VERSION ""

NS_ :

BS_:

BU_: AHRS PDM BCU STW Gigabox ADL Bosch_YawRate_Sensor CSI_5_REAR_left CSI_6_REAR_right CSI_4_DASH CSI_3_Front_Middle ECU Host CSI_1_Front_Left CSI_2_Front_Right
VAL_TABLE_ ERROR_IDs 5 "Lost BMS Message (BMS FAULT)" 4 "Lost BMS Message" 3 "Overtemperature" 2 "Undervoltage" 1 "Overvoltage" 0 "undefined" ;
VAL_TABLE_ SC_open 1 "SC closed" 0 "SC open" ;
VAL_TABLE_ TLE_Diag_Channel 3 "normal function" 2 "Overload, Overtemp" 1 "open Load" 0 "short to GND" ;
VAL_TABLE_ AIR_State 2 "AIR CLOSED" 1 "PRECHARGE" 0 "AIR OPEN" -1 "AIR ERROR" ;
VAL_TABLE_ SC 1 "ok" 0 "fault" ;
VAL_TABLE_ Channel_Status 2 "OVERLOAD" 1 "ON" 0 "OFF" ;
VAL_TABLE_ Status_Continental 4369 "Reserved" 4368 "Signal faulty" 4353 "Sensor does not exist" 4113 "Reserved" 4097 "Sensor does not exist" 4096 "Signal within range" 273 "Reserved" 257 "Sensor does not exist" 256 "Signal within range" 17 "Reserved" 1 "Sensor does not exist" 0 "Signal within range" 4352 "Signal within range" 4112 "Signal faulty" 272 "Signal faulty" 16 "Signal faulty" ;
VAL_TABLE_ AnAus 1 "1" 0 "0" ;
VAL_TABLE_ Mount_Position 7 "rotated +270 z reflection xy" 6 "rotated +180 z reflection xy" 5 "rotated +90 zreflection xy" 4 "Standard reflection xy" 3 "rotated +270 z" 2 "rotated +180 z" 1 "rotated +90 z" 0 "Standard" ;
VAL_TABLE_ Format_CAN_Signals 1 "Motorola Format" 0 "Intel Format" ;

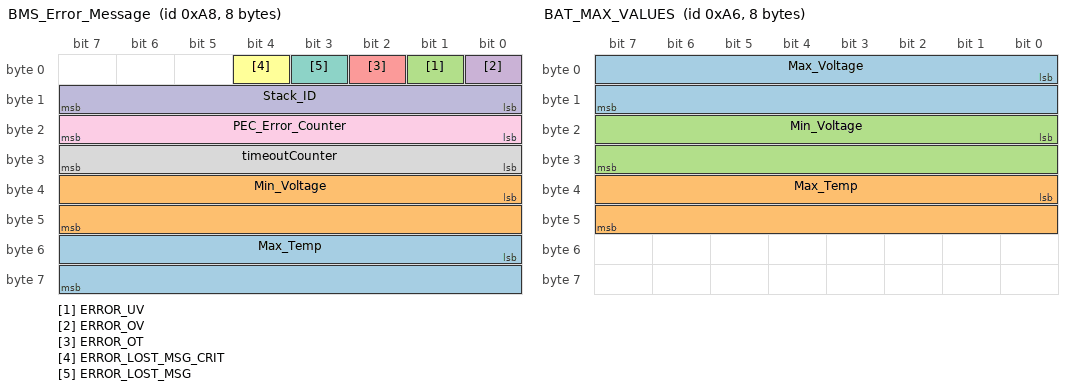
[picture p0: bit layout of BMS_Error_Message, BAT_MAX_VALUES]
BO_ 168 BMS_Error_Message: 8 BCU
 SG_ Max_Temp : 48|16@1- (0.01,0) [0|0] "°C" Vector__XXX
 SG_ Min_Voltage : 32|16@1+ (0.0001,0) [0|6.5535] "" Vector__XXX
 SG_ ERROR_UV : 1|1@1+ (1,0) [0|0] "" Vector__XXX
 SG_ ERROR_OV : 0|1@1+ (1,0) [0|0] "" Vector__XXX
 SG_ ERROR_OT : 2|1@1+ (1,0) [0|0] "" Vector__XXX
 SG_ ERROR_LOST_MSG_CRIT : 4|1@1+ (1,0) [0|0] "" Vector__XXX
 SG_ ERROR_LOST_MSG : 3|1@1+ (1,0) [0|0] "" Vector__XXX
 SG_ timeoutCounter : 24|8@1+ (1,0) [0|0] "" Vector__XXX
 SG_ PEC_Error_Counter : 16|8@1+ (1,0) [0|0] "" Vector__XXX
 SG_ Stack_ID : 8|8@1+ (1,0) [0|0] "" Vector__XXX

BO_ 166 BAT_MAX_VALUES: 8 BCU
 SG_ Max_Voltage : 0|16@1+ (0.0001,0) [0|6.5535] "V" Vector__XXX
 SG_ Max_Temp : 32|16@1- (0.01,0) [0|0] "°C" Vector__XXX
 SG_ Min_Voltage : 16|16@1+ (0.0001,0) [0|6.5535] "" Vector__XXX

BO_ 1540 IMD_Control_CSI0: 8 BCU
 SG_ IMD_LED : 0|1@1+ (1,0) [0|0] "" Vector__XXX

BO_ 1556 Precharge_LED_Control_CSI1: 8 BCU
 SG_ Precharge_LED : 0|1@1- (1,0) [0|0] "" Vector__XXX

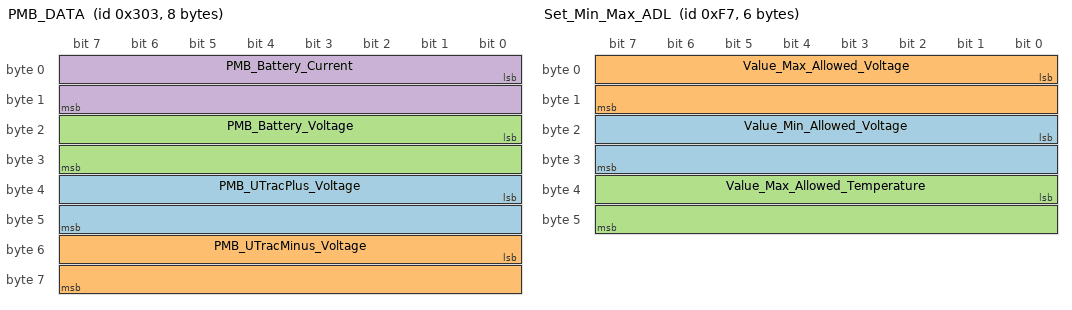
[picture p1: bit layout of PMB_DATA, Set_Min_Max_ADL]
BO_ 771 PMB_DATA: 8 STW
 SG_ PMB_UTracPlus_Voltage : 32|16@1- (0.025,0) [-820|820] "V"  Gigabox
 SG_ PMB_UTracMinus_Voltage : 48|16@1- (0.025,0) [-820|820] "V"  Gigabox
 SG_ PMB_Battery_Voltage : 16|16@1- (0.025,0) [-819.2|819.175] "V"  Gigabox
 SG_ PMB_Battery_Current : 0|16@1- (0.025,0) [-819.2|819.175] "A"  Gigabox

BO_ 167 AIR_Stuck: 4 BCU
 SG_ AIR_Stuck_Plus : 0|16@1- (1,0) [0|0] ""  ADL
 SG_ AIR_Stuck_Minus : 16|16@1- (1,0) [0|0] ""  ADL

BO_ 247 Set_Min_Max_ADL: 6 ADL
 SG_ Value_Min_Allowed_Voltage : 16|16@1+ (0.0001,0) [0|0] "V" Vector__XXX
 SG_ Value_Max_Allowed_Voltage : 0|16@1+ (0.0001,0) [0|0] "V" Vector__XXX
 SG_ Value_Max_Allowed_Temperature : 32|16@1- (0.01,0) [0|0] "C" Vector__XXX

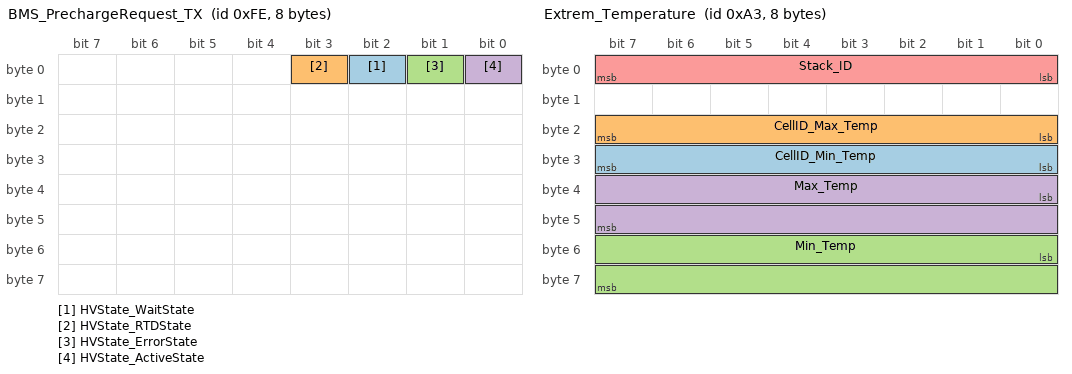
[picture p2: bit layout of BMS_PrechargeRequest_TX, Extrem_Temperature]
BO_ 254 BMS_PrechargeRequest_TX: 8 Gigabox
 SG_ HVState_WaitState : 2|1@1+ (1,0) [0|0] "" Vector__XXX
 SG_ HVState_RTDState : 3|1@1+ (1,0) [0|0] "" Vector__XXX
 SG_ HVState_ErrorState : 1|1@1+ (1,0) [0|0] "" Vector__XXX
 SG_ HVState_ActiveState : 0|1@1+ (1,0) [0|0] "" Vector__XXX

BO_ 163 Extrem_Temperature: 8 BCU
 SG_ CellID_Min_Temp : 24|8@1+ (1,0) [0|0] "" Vector__XXX
 SG_ CellID_Max_Temp : 16|8@1+ (1,0) [0|0] "" Vector__XXX
 SG_ Min_Temp : 48|16@1- (0.01,0) [0|0] "°C" Vector__XXX
 SG_ Max_Temp : 32|16@1- (0.01,0) [0|0] "°C" Vector__XXX
 SG_ Stack_ID : 0|8@1+ (1,0) [0|0] "" Vector__XXX

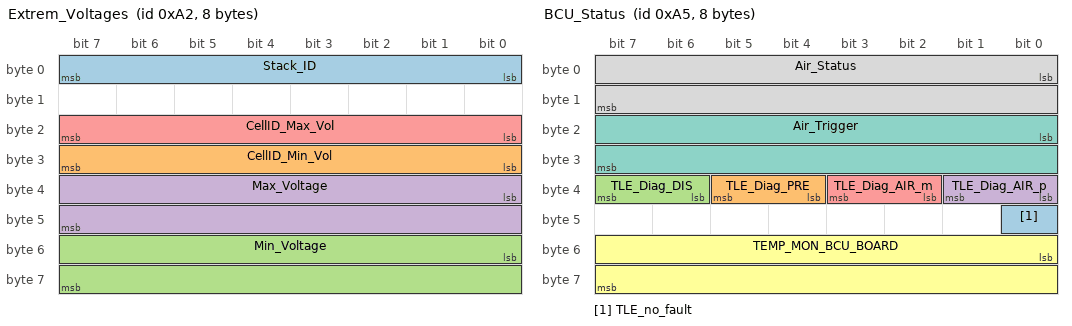
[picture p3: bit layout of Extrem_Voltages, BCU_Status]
BO_ 162 Extrem_Voltages: 8 BCU
 SG_ Stack_ID : 0|8@1+ (1,0) [0|0] "" Vector__XXX
 SG_ CellID_Min_Vol : 24|8@1+ (1,0) [0|0] "" Vector__XXX
 SG_ Min_Voltage : 48|16@1+ (0.0001,0) [0|6.5535] "" Vector__XXX
 SG_ Max_Voltage : 32|16@1+ (0.0001,0) [0|6.5535] "V" Vector__XXX
 SG_ CellID_Max_Vol : 16|8@1+ (1,0) [0|0] "" Vector__XXX

BO_ 165 BCU_Status: 8 BCU
 SG_ TLE_no_fault : 40|1@1+ (1,0) [0|0] "" Vector__XXX
 SG_ TLE_Diag_PRE : 36|2@1+ (1,0) [0|0] "" Vector__XXX
 SG_ TLE_Diag_DIS : 38|2@1+ (1,0) [0|0] "" Vector__XXX
 SG_ TLE_Diag_AIR_p : 32|2@1+ (1,0) [0|0] "" Vector__XXX
 SG_ TLE_Diag_AIR_m : 34|2@1+ (1,0) [0|0] "" Vector__XXX
 SG_ TEMP_MON_BCU_BOARD : 48|16@1- (0.0125,0) [0|0] "°C" Vector__XXX
 SG_ Air_Trigger : 16|16@1- (1,0) [0|0] "" Vector__XXX
 SG_ Air_Status : 0|16@1- (1,0) [0|0] "" Vector__XXX

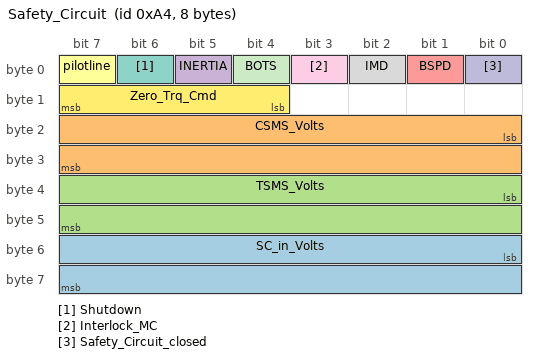
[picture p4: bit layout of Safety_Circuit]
BO_ 164 Safety_Circuit: 8 BCU
 SG_ SC_in_Volts : 48|16@1+ (0.001,0) [0|0] "V" Vector__XXX
 SG_ CSMS_Volts : 16|16@1+ (0.001,0) [0|0] "V" Vector__XXX
 SG_ TSMS_Volts : 32|16@1+ (0.001,0) [0|0] "V" Vector__XXX
 SG_ INERTIA : 5|1@1+ (1,0) [0|1] ""  ADL
 SG_ BSPD : 1|1@1+ (1,0) [0|1] ""  ADL
 SG_ pilotline : 7|1@1+ (1,0) [0|1] ""  ADL
 SG_ Shutdown : 6|1@1+ (1,0) [0|1] ""  ADL
 SG_ IMD : 2|1@1+ (1,0) [0|1] ""  ADL
 SG_ Interlock_MC : 3|1@1+ (1,0) [0|1] ""  ADL
 SG_ Safety_Circuit_closed : 0|1@1+ (1,0) [0|1] ""  ADL
 SG_ BOTS : 4|1@1+ (1,0) [0|1] ""  ADL
 SG_ Zero_Trq_Cmd : 12|4@1+ (1,0) [0|0] ""  ADL,Gigabox

BO_ 1572 BMS_LED_Control_CSI2: 8 ADL
 SG_ BMS_LED : 0|1@1- (1,0) [0|0] "" Vector__XXX

BO_TX_BU_ 771 : BCU,STW;

EV_ env_HVState_ActiveState: 0 [0|0] "" 0 1 DUMMY_NODE_VECTOR0 Vector__XXX;

EV_ Env_MountPosition: 0 [0|0] "" 0 2 DUMMY_NODE_VECTOR0 Vector__XXX;

EV_ Env_AnAus: 0 [0|0] "" 0 3 DUMMY_NODE_VECTOR0 Vector__XXX;

EV_ Env_Timer: 0 [5|25] "" 20 4 DUMMY_NODE_VECTOR0 Vector__XXX;

EV_ Env_Reset: 0 [0|0] "" 0 5 DUMMY_NODE_VECTOR0 Vector__XXX;

EV_ Env_KeepQuiet: 0 [0|1] "" 0 6 DUMMY_NODE_VECTOR0 Vector__XXX;

EV_ Env_DeleteErrMem: 0 [0|1] "" 0 7 DUMMY_NODE_VECTOR0 Vector__XXX;

EV_ Env_MsgCounter: 0 [0|255] "" 0 8 DUMMY_NODE_VECTOR0 Vector__XXX;

EV_ Env_Format_CAN_Signals: 0 [0|1] "" 0 9 DUMMY_NODE_VECTOR0 Vector__XXX;

EV_ Env_Checksum: 0 [0|0] "" 0 10 DUMMY_NODE_VECTOR0 Vector__XXX;

BA_DEF_ SG_  "GenSigSendType" ENUM  "Cyclic","OnWrite","OnWriteWithRepetition","OnChange","OnChangeWithRepetition","IfActive","IfActiveWithRepetition","NoSigSendType";
BA_DEF_ BO_  "GenMsgSendType" ENUM  "Cyclic","not_used","not_used","not_used","not_used","Cyclic","not_used","IfActive","NoMsgSendType";
BA_DEF_  "DBName" STRING ;
BA_DEF_  "Bus Speed" STRING ;
BA_DEF_  "BusType" STRING ;
BA_DEF_DEF_  "GenSigSendType" "Cyclic";
BA_DEF_DEF_  "GenMsgSendType" "NoMsgSendType";
BA_DEF_DEF_  "DBName" "";
BA_DEF_DEF_  "Bus Speed" "500k";
BA_DEF_DEF_  "BusType" "";
BA_ "BusType" "CAN";
BA_ "DBName" "Vehicle_CAN";
VAL_ 165 TLE_Diag_PRE 3 "normal function" 2 "Overload, Overtemp" 1 "open Load" 0 "short to GND" ;
VAL_ 165 TLE_Diag_DIS 3 "normal function" 2 "Overload, Overtemp" 1 "open Load" 0 "short to GND" ;
VAL_ 165 TLE_Diag_AIR_p 3 "normal function" 2 "Overload, Overtemp" 1 "open Load" 0 "short to GND" ;
VAL_ 165 TLE_Diag_AIR_m 3 "normal function" 2 "Overload, Overtemp" 1 "open Load" 0 "short to GND" ;
VAL_ 165 Air_Trigger 2 "AIR CLOSED" 1 "PRECHARGE" 0 "AIR OPEN" -1 "AIR ERROR" ;
VAL_ 165 Air_Status 2 "AIR CLOSED" 1 "PRECHARGE" 0 "AIR OPEN" -1 "AIR ERROR" ;
VAL_ 164 INERTIA 1 "ok" 0 "fault" ;
VAL_ 164 BSPD 1 "ok" 0 "fault" ;
VAL_ 164 pilotline 1 "ok" 0 "fault" ;
VAL_ 164 Shutdown 1 "ok" 0 "fault" ;
VAL_ 164 IMD 1 "ok" 0 "fault" ;
VAL_ 164 Interlock_MC 1 "ok" 0 "fault" ;
VAL_ 164 Safety_Circuit_closed 1 "SC closed" 0 "SC open" ;
VAL_ 164 BOTS 1 "ok" 0 "fault" ;
